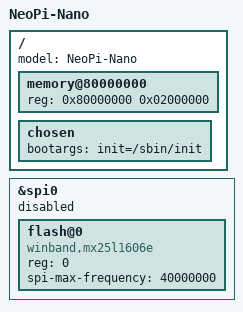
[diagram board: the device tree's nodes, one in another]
/* SPDX-License-Identifier: GPL-2.0-or-later */
/dts-v1/;
#include "sunxi/suniv.dtsi"

/ {
    model = "NeoPi-Nano";

    memory@80000000 {
        device_type = "memory";
        reg = <0x80000000 0x02000000>;
    };

    chosen {
        bootargs = "init=/sbin/init";
    };
};

&spi0 {
    status = "disabled";

    flash@0 {
        #address-cells = <1>;
        #size-cells = <1>;
        compatible = "winband,mx25l1606e", "jedec,spi-nor";
        reg = <0>;
        spi-max-frequency = <40000000>;
    };
};
